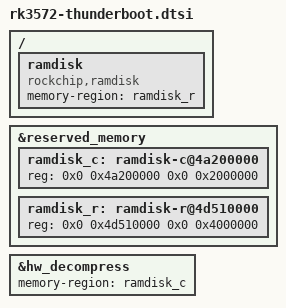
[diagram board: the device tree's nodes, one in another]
// SPDX-License-Identifier: (GPL-2.0+ OR MIT)
/*
 * Copyright (c) 2026 Rockchip Electronics Co., Ltd.
 */

/ {
	ramdisk: ramdisk {
		compatible = "rockchip,ramdisk";
		memory-region = <&ramdisk_r>;
	};
};

&reserved_memory {
	ramdisk_c: ramdisk-c@4a200000 {
		reg = <0x0 0x4a200000 0x0 0x2000000>;
	};

	ramdisk_r: ramdisk-r@4d510000 {
		reg = <0x0 0x4d510000 0x0 0x4000000>;
	};
};

&hw_decompress {
	memory-region = <&ramdisk_c>;
	status = "okay";
};
